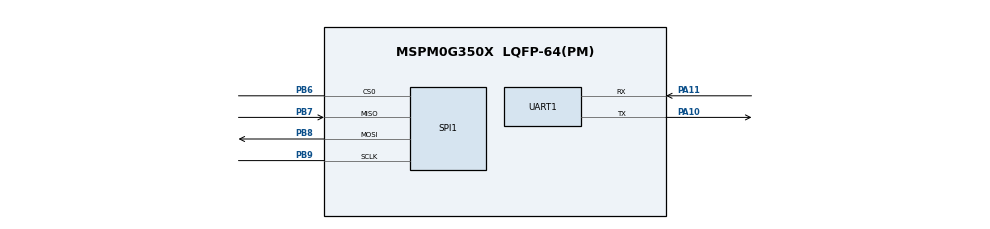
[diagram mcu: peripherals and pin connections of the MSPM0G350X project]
/**
 * @cliArgs --device "MSPM0G350X" --part "Default" --package "LQFP-64(PM)" --product "mspm0_sdk@2.10.00.04"
 * @versions {"tool":"1.26.2+4477"}
 */

/**
 * Import the modules used in this configuration.
 */
const GPIO   = scripting.addModule("/ti/driverlib/GPIO", {}, false);
const GPIO1  = GPIO.addInstance();
const PWM    = scripting.addModule("/ti/driverlib/PWM", {}, false);
const PWM1   = PWM.addInstance();
const SPI    = scripting.addModule("/ti/driverlib/SPI", {}, false);
const SPI1   = SPI.addInstance();
const SYSCTL = scripting.addModule("/ti/driverlib/SYSCTL");
const UART   = scripting.addModule("/ti/driverlib/UART", {}, false);
const UART1  = UART.addInstance();

/**
 * Write custom configuration values to the imported modules.
 */
GPIO1.$name                   = "GPIO_GRP_0";
GPIO1.associatedPins[0].$name = "PIN_0";

const Board = scripting.addModule("/ti/driverlib/Board", {}, false);

PWM1.$name               = "PWM_0";
PWM1.PWM_CHANNEL_0.$name = "ti_driverlib_pwm_PWMTimerCC0";
PWM1.PWM_CHANNEL_1.$name = "ti_driverlib_pwm_PWMTimerCC1";
PWM1.ccp0PinConfig.$name = "ti_driverlib_gpio_GPIOPinGeneric6";
PWM1.ccp1PinConfig.$name = "ti_driverlib_gpio_GPIOPinGeneric7";

SPI1.$name                      = "SPI_0";
SPI1.enabledInterrupts          = ["PARITY_ERROR","RX","RX_FULL","RX_OVERFLOW","RX_TIMEOUT","TX","TX_UNDERFLOW"];
SPI1.rxFifoThreshold            = "DL_SPI_RX_FIFO_LEVEL_ONE_FRAME";
SPI1.peripheral.sclkPin.$assign = "PB9";
SPI1.peripheral.mosiPin.$assign = "PB8";
SPI1.peripheral.misoPin.$assign = "PB7";
SPI1.peripheral.cs0Pin.$assign  = "PB6";
SPI1.sclkPinConfig.$name        = "ti_driverlib_gpio_GPIOPinGeneric0";
SPI1.mosiPinConfig.$name        = "ti_driverlib_gpio_GPIOPinGeneric1";
SPI1.misoPinConfig.$name        = "ti_driverlib_gpio_GPIOPinGeneric2";
SPI1.cs0PinConfig.$name         = "ti_driverlib_gpio_GPIOPinGeneric3";

SYSCTL.clockTreeEn           = true;
SYSCTL.forceDefaultClkConfig = true;

UART1.rxFifoThreshold                  = "DL_UART_RX_FIFO_LEVEL_ONE_ENTRY";
UART1.enableDMARX                      = false;
UART1.enableDMATX                      = false;
UART1.enabledInterrupts                = ["RX"];
UART1.$name                            = "UART_BRIDGE";
UART1.peripheral.$assign               = "UART0";
UART1.peripheral.rxPin.$assign         = "PA11";
UART1.peripheral.txPin.$assign         = "PA10";
UART1.txPinConfig.$name                = "ti_driverlib_gpio_GPIOPinGeneric4";
UART1.txPinConfig.direction            = scripting.forceWrite("OUTPUT");
UART1.txPinConfig.hideOutputInversion  = scripting.forceWrite(false);
UART1.txPinConfig.onlyInternalResistor = scripting.forceWrite(false);
UART1.txPinConfig.passedPeripheralType = scripting.forceWrite("Digital");
UART1.rxPinConfig.$name                = "ti_driverlib_gpio_GPIOPinGeneric5";
UART1.rxPinConfig.hideOutputInversion  = scripting.forceWrite(false);
UART1.rxPinConfig.onlyInternalResistor = scripting.forceWrite(false);
UART1.rxPinConfig.passedPeripheralType = scripting.forceWrite("Digital");

/**
 * Pinmux solution for unlocked pins/peripherals. This ensures that minor changes to the automatic solver in a future
 * version of the tool will not impact the pinmux you originally saw.  These lines can be completely deleted in order to
 * re-solve from scratch.
 */
GPIO1.associatedPins[0].pin.$suggestSolution = "PB13";
Board.peripheral.$suggestSolution            = "DEBUGSS";
Board.peripheral.swclkPin.$suggestSolution   = "PA20";
Board.peripheral.swdioPin.$suggestSolution   = "PA19";
PWM1.peripheral.$suggestSolution             = "TIMA0";
PWM1.peripheral.ccp0Pin.$suggestSolution     = "PA0";
PWM1.peripheral.ccp1Pin.$suggestSolution     = "PA1";
SPI1.peripheral.$suggestSolution             = "SPI1";
